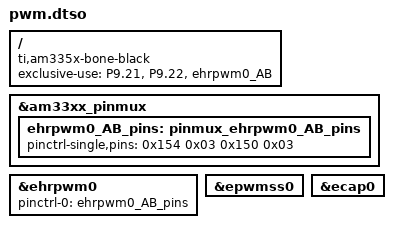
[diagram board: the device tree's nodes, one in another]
/dts-v1/;
/plugin/;

/ {
    compatible = "ti,am335x-bone-black", "ti,am335x-bone", "ti,am33xx";
    exclusive-use = "P9.21","P9.22","ehrpwm0_AB";
};

&am33xx_pinmux {
     ehrpwm0_AB_pins: pinmux_ehrpwm0_AB_pins {
        pinctrl-single,pins = <
             0x154 0x03        /* P9.21 */
             0x150 0x03        /* P9.22 */
        >;
    }; 
};

&ehrpwm0 {
    status = "okay";
    pinctrl-names = "default";
    pinctrl-0 = <&ehrpwm0_AB_pins>;
};

&epwmss0 { 
   status = "okay";
};

&ecap0 { 
   status = "okay";
};




